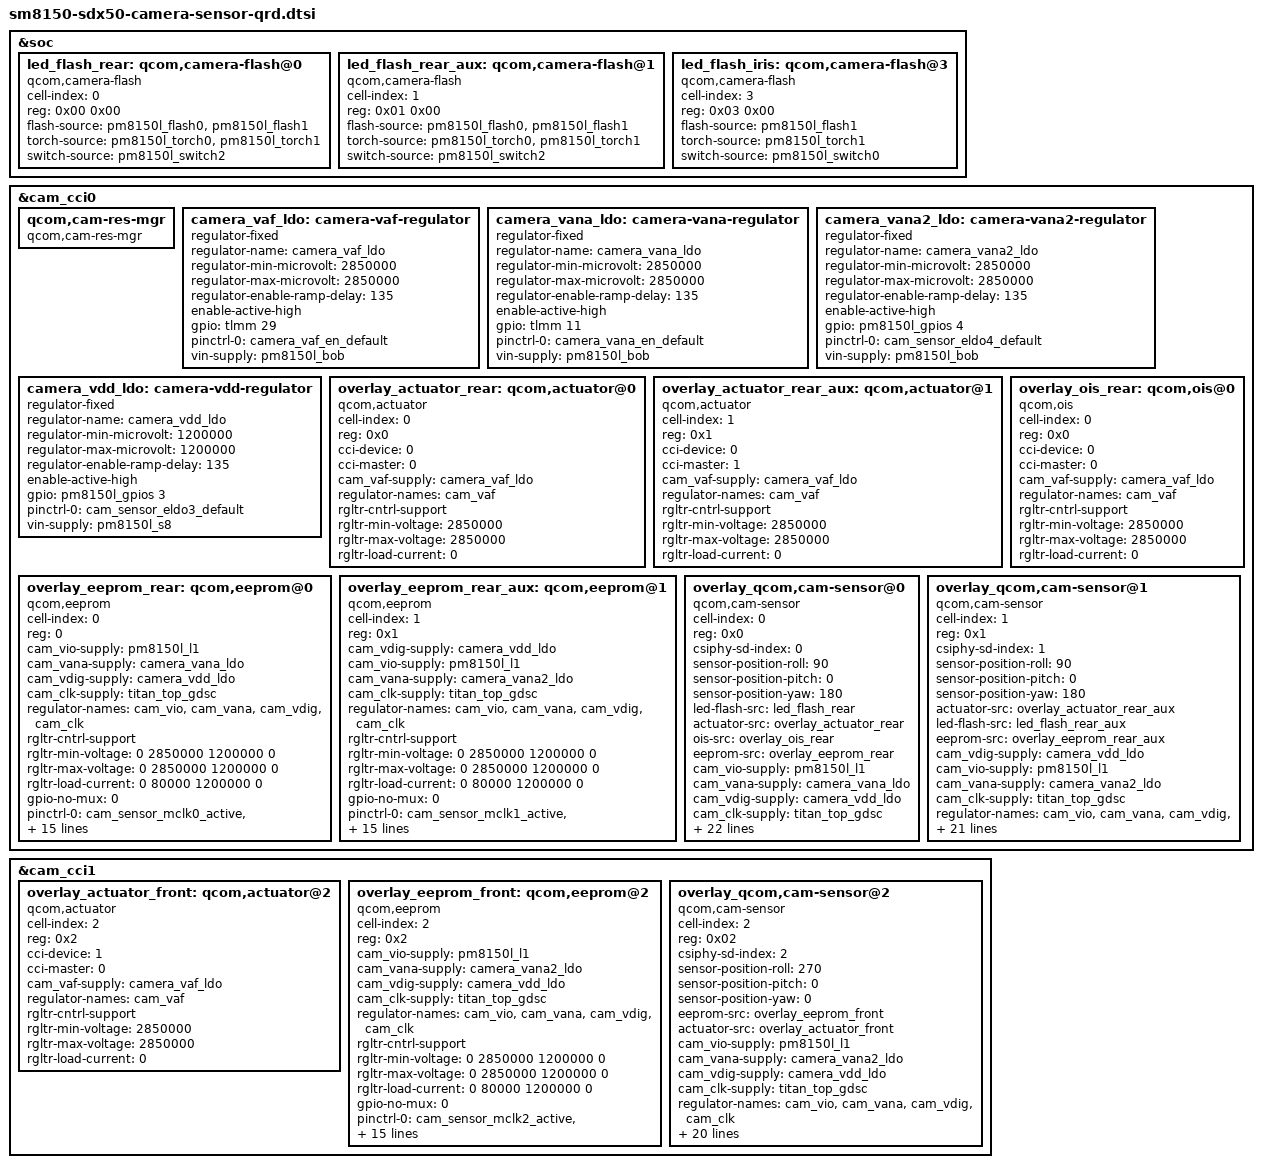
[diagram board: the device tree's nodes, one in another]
/*
 * Copyright (c) 2018-2019 The Linux Foundation. All rights reserved.
 *
 * This program is free software; you can redistribute it and/or modify
 * it under the terms of the GNU General Public License version 2 and
 * only version 2 as published by the Free Software Foundation.
 *
 * This program is distributed in the hope that it will be useful,
 * but WITHOUT ANY WARRANTY; without even the implied warranty of
 * MERCHANTABILITY or FITNESS FOR A PARTICULAR PURPOSE.  See the
 * GNU General Public License for more details.
 */

#include <dt-bindings/clock/qcom,camcc-sm8150.h>

&soc {
	#address-cells = <1>;
	#size-cells = <1>;

	led_flash_rear: qcom,camera-flash@0 {
		cell-index = <0>;
		reg = <0x00 0x00>;
		compatible = "qcom,camera-flash";
		flash-source = <&pm8150l_flash0 &pm8150l_flash1>;
		torch-source = <&pm8150l_torch0 &pm8150l_torch1>;
		switch-source = <&pm8150l_switch2>;
		status = "ok";
	};

	led_flash_rear_aux: qcom,camera-flash@1 {
		cell-index = <1>;
		reg = <0x01 0x00>;
		compatible = "qcom,camera-flash";
		flash-source = <&pm8150l_flash0 &pm8150l_flash1>;
		torch-source = <&pm8150l_torch0 &pm8150l_torch1>;
		switch-source = <&pm8150l_switch2>;
		status = "ok";
	};

	led_flash_iris: qcom,camera-flash@3 {
		cell-index = <3>;
		reg = <0x03 0x00>;
		compatible = "qcom,camera-flash";
		flash-source = <&pm8150l_flash1>;
		torch-source = <&pm8150l_torch1>;
		switch-source = <&pm8150l_switch0>;
		status = "ok";
	};
};

&cam_cci0 {
	#address-cells = <1>;
	#size-cells = <0>;

	qcom,cam-res-mgr {
		compatible = "qcom,cam-res-mgr";
		status = "ok";
	};
	camera_vaf_ldo: camera-vaf-regulator {
		compatible = "regulator-fixed";
		regulator-name = "camera_vaf_ldo";
		regulator-min-microvolt = <2850000>;
		regulator-max-microvolt = <2850000>;
		regulator-enable-ramp-delay = <135>; //Check
		enable-active-high;
		gpio = <&tlmm 29 0>;
		pinctrl-names = "default";
		pinctrl-0 = <&camera_vaf_en_default>;
		vin-supply = <&pm8150l_bob>;
	};

	camera_vana_ldo: camera-vana-regulator {
		compatible = "regulator-fixed";
		regulator-name = "camera_vana_ldo";
		regulator-min-microvolt = <2850000>;
		regulator-max-microvolt = <2850000>;
		regulator-enable-ramp-delay = <135>; // Check
		enable-active-high;
		gpio = <&tlmm 11 0>;
		pinctrl-names = "default";
		pinctrl-0 = <&camera_vana_en_default>;
		vin-supply = <&pm8150l_bob>;
	};

	camera_vana2_ldo: camera-vana2-regulator {
		compatible = "regulator-fixed";
		regulator-name = "camera_vana2_ldo";
		regulator-min-microvolt = <2850000>;
		regulator-max-microvolt = <2850000>;
		regulator-enable-ramp-delay = <135>; // Check
		enable-active-high;
		gpio = <&pm8150l_gpios 4 0>;
		pinctrl-names = "default";
		pinctrl-0 = <&cam_sensor_eldo4_default>;
		vin-supply = <&pm8150l_bob>;
	};

	camera_vdd_ldo: camera-vdd-regulator {
		compatible = "regulator-fixed";
		regulator-name = "camera_vdd_ldo";
		regulator-min-microvolt = <1200000>;
		regulator-max-microvolt = <1200000>;
		regulator-enable-ramp-delay = <135>; // Check
		enable-active-high;
		gpio = <&pm8150l_gpios 3 0>;
		pinctrl-names = "default";
		pinctrl-0 = <&cam_sensor_eldo3_default>;
		vin-supply = <&pm8150l_s8>;
	};

	overlay_actuator_rear: qcom,actuator@0 {
		cell-index = <0>;
		reg = <0x0>;
		compatible = "qcom,actuator";
		cci-device = <0>;
		cci-master = <0>;
		cam_vaf-supply = <&camera_vaf_ldo>;
		regulator-names = "cam_vaf";
		rgltr-cntrl-support;
		rgltr-min-voltage = <2850000>;
		rgltr-max-voltage = <2850000>;
		rgltr-load-current = <0>;
	};

	overlay_actuator_rear_aux: qcom,actuator@1 {
		cell-index = <1>;
		reg = <0x1>;
		compatible = "qcom,actuator";
		cci-device = <0>;
		cci-master = <1>;
		cam_vaf-supply = <&camera_vaf_ldo>;
		regulator-names = "cam_vaf";
		rgltr-cntrl-support;
		rgltr-min-voltage = <2850000>;
		rgltr-max-voltage = <2850000>;
		rgltr-load-current = <0>;
	};

	overlay_ois_rear: qcom,ois@0 {
		cell-index = <0>;
		reg = <0x0>;
		compatible = "qcom,ois";
		cci-device = <0>;
		cci-master = <0>;
		cam_vaf-supply = <&camera_vaf_ldo>;
		regulator-names = "cam_vaf";
		rgltr-cntrl-support;
		rgltr-min-voltage = <2850000>;
		rgltr-max-voltage = <2850000>;
		rgltr-load-current = <0>;
		status = "ok";
	};

	overlay_eeprom_rear: qcom,eeprom@0 {
		cell-index = <0>;
		reg = <0>;
		compatible = "qcom,eeprom";
		cam_vio-supply = <&pm8150l_l1>;
		cam_vana-supply = <&camera_vana_ldo>;
		cam_vdig-supply = <&camera_vdd_ldo>;
		cam_clk-supply = <&titan_top_gdsc>;
		regulator-names = "cam_vio", "cam_vana", "cam_vdig",
			"cam_clk";
		rgltr-cntrl-support;
		rgltr-min-voltage = <0 2850000 1200000 0>;
		rgltr-max-voltage = <0 2850000 1200000 0>;
		rgltr-load-current = <0 80000 1200000 0>;
		gpio-no-mux = <0>;
		pinctrl-names = "cam_default", "cam_suspend";
		pinctrl-0 = <&cam_sensor_mclk0_active
				&cam_sensor_active_rear>;
		pinctrl-1 = <&cam_sensor_mclk0_suspend
				&cam_sensor_suspend_rear>;
		gpios = <&tlmm 13 0>,
			<&tlmm 28 0>;
		gpio-reset = <1>;
		gpio-req-tbl-num = <0 1>;
		gpio-req-tbl-flags = <1 0>;
		gpio-req-tbl-label = "CAMIF_MCLK0",
					"CAM_RESET0";
		sensor-position = <0>;
		sensor-mode = <0>;
		cci-device = <0>;
		cci-master = <0>;
		status = "ok";
		clocks = <&clock_camcc CAM_CC_MCLK0_CLK>;
		clock-names = "cam_clk";
		clock-cntl-level = "turbo";
		clock-rates = <24000000>;
	};

	overlay_eeprom_rear_aux: qcom,eeprom@1 {
		cell-index = <1>;
		reg = <0x1>;
		compatible = "qcom,eeprom";
		cam_vdig-supply = <&camera_vdd_ldo>;
		cam_vio-supply = <&pm8150l_l1>;
		cam_vana-supply = <&camera_vana2_ldo>;
		cam_clk-supply = <&titan_top_gdsc>;
		regulator-names = "cam_vio", "cam_vana", "cam_vdig",
			"cam_clk";
		rgltr-cntrl-support;
		rgltr-min-voltage = <0 2850000 1200000 0>;
		rgltr-max-voltage = <0 2850000 1200000 0>;
		rgltr-load-current = <0 80000 1200000 0>;
		gpio-no-mux = <0>;
		pinctrl-names = "cam_default", "cam_suspend";
		pinctrl-0 = <&cam_sensor_mclk1_active
				 &cam_sensor_active_rear_aux>;
		pinctrl-1 = <&cam_sensor_mclk1_suspend
				 &cam_sensor_suspend_rear_aux>;
		gpios = <&tlmm 14 0>,
			<&tlmm 30 0>;
		gpio-reset = <1>;
		gpio-req-tbl-num = <0 1>;
		gpio-req-tbl-flags = <1 0>;
		gpio-req-tbl-label = "CAMIF_MCLK1",
					"CAM_RESET1";
		sensor-position = <0>;
		sensor-mode = <0>;
		cci-device = <0>;
		cci-master = <1>;
		status = "ok";
		clocks = <&clock_camcc CAM_CC_MCLK2_CLK>;
		clock-names = "cam_clk";
		clock-cntl-level = "turbo";
		clock-rates = <24000000>;
	};

	overlay_qcom,cam-sensor@0 {
		cell-index = <0>;
		compatible = "qcom,cam-sensor";
		reg = <0x0>;
		csiphy-sd-index = <0>;
		sensor-position-roll = <90>;
		sensor-position-pitch = <0>;
		sensor-position-yaw = <180>;
		led-flash-src = <&led_flash_rear>;
		actuator-src = <&overlay_actuator_rear>;
		ois-src = <&overlay_ois_rear>;
		eeprom-src = <&overlay_eeprom_rear>;
		cam_vio-supply = <&pm8150l_l1>;
		cam_vana-supply = <&camera_vana_ldo>;
		cam_vdig-supply = <&camera_vdd_ldo>;
		cam_clk-supply = <&titan_top_gdsc>;
		regulator-names = "cam_vio", "cam_vana", "cam_vdig",
			"cam_clk";
		rgltr-cntrl-support;
		rgltr-min-voltage = <0 2850000 1200000 0>;
		rgltr-max-voltage = <0 2850000 1200000 0>;
		rgltr-load-current = <0 80000 1200000 0>;
		gpio-no-mux = <0>;
		pinctrl-names = "cam_default", "cam_suspend";
		pinctrl-0 = <&cam_sensor_mclk0_active
				&cam_sensor_active_rear>;
		pinctrl-1 = <&cam_sensor_mclk0_suspend
				&cam_sensor_suspend_rear>;
		gpios = <&tlmm 13 0>,
			<&tlmm 28 0>;
		gpio-reset = <1>;
		gpio-req-tbl-num = <0 1>;
		gpio-req-tbl-flags = <1 0>;
		gpio-req-tbl-label = "CAMIF_MCLK0",
					"CAM_RESET0";
		sensor-mode = <0>;
		cci-device = <0>;
		cci-master = <0>;
		status = "ok";
		clocks = <&clock_camcc CAM_CC_MCLK0_CLK>;
		clock-names = "cam_clk";
		clock-cntl-level = "turbo";
		clock-rates = <24000000>;
	};

	overlay_qcom,cam-sensor@1 {
		cell-index = <1>;
		compatible = "qcom,cam-sensor";
		reg = <0x1>;
		csiphy-sd-index = <1>;
		sensor-position-roll = <90>;
		sensor-position-pitch = <0>;
		sensor-position-yaw = <180>;
		actuator-src = <&overlay_actuator_rear_aux>;
		led-flash-src = <&led_flash_rear_aux>;
		eeprom-src = <&overlay_eeprom_rear_aux>;
		cam_vdig-supply = <&camera_vdd_ldo>;
		cam_vio-supply = <&pm8150l_l1>;
		cam_vana-supply = <&camera_vana2_ldo>;
		cam_clk-supply = <&titan_top_gdsc>;
		regulator-names = "cam_vio", "cam_vana", "cam_vdig",
			"cam_clk";
		rgltr-cntrl-support;
		rgltr-min-voltage = <0 2850000 1200000 0>;
		rgltr-max-voltage = <0 2850000 1200000 0>;
		rgltr-load-current = <0 80000 1200000 0>;
		gpio-no-mux = <0>;
		pinctrl-names = "cam_default", "cam_suspend";
		pinctrl-0 = <&cam_sensor_mclk1_active
				&cam_sensor_active_rear_aux>;
		pinctrl-1 = <&cam_sensor_mclk1_suspend
				&cam_sensor_suspend_rear_aux>;
		gpios = <&tlmm 14 0>,
			<&tlmm 30 0>;
		gpio-reset = <1>;
		gpio-req-tbl-num = <0 1>;
		gpio-req-tbl-flags = <1 0>;
		gpio-req-tbl-label = "CAMIF_MCLK1",
					"CAM_RESET1";
		sensor-mode = <0>;
		cci-device = <0>;
		cci-master = <1>;
		status = "ok";
		clocks = <&clock_camcc CAM_CC_MCLK1_CLK>;
		clock-names = "cam_clk";
		clock-cntl-level = "turbo";
		clock-rates = <24000000>;
	};
};

&cam_cci1 {
	#address-cells = <1>;
	#size-cells = <0>;
	overlay_actuator_front: qcom,actuator@2 {
		cell-index = <2>;
		reg = <0x2>;
		compatible = "qcom,actuator";
		cci-device = <1>;
		cci-master = <0>;
		cam_vaf-supply = <&camera_vaf_ldo>;
		regulator-names = "cam_vaf";
		rgltr-cntrl-support;
		rgltr-min-voltage = <2850000>;
		rgltr-max-voltage = <2850000>;
		rgltr-load-current = <0>;
	};
	overlay_eeprom_front: qcom,eeprom@2 {
		cell-index = <2>;
		reg = <0x2>;
		compatible = "qcom,eeprom";
		cam_vio-supply = <&pm8150l_l1>;
		cam_vana-supply = <&camera_vana2_ldo>;
		cam_vdig-supply = <&camera_vdd_ldo>;
		cam_clk-supply = <&titan_top_gdsc>;
		regulator-names = "cam_vio", "cam_vana", "cam_vdig",
			"cam_clk";
		rgltr-cntrl-support;
		rgltr-min-voltage = <0 2850000 1200000 0>;
		rgltr-max-voltage = <0 2850000 1200000 0>;
		rgltr-load-current = <0 80000 1200000 0>;
		gpio-no-mux = <0>;
		pinctrl-names = "cam_default", "cam_suspend";
		pinctrl-0 = <&cam_sensor_mclk2_active
				 &cam_sensor_active_front>;
		pinctrl-1 = <&cam_sensor_mclk2_suspend
				 &cam_sensor_suspend_front>;
		gpios = <&tlmm 15 0>,
			<&tlmm 12 0>;
		gpio-reset = <1>;
		gpio-req-tbl-num = <0 1>;
		gpio-req-tbl-flags = <1 0>;
		gpio-req-tbl-label = "CAMIF_MCLK2",
					"CAM_RESET2";
		sensor-position = <1>;
		sensor-mode = <0>;
		cci-device = <1>;
		cci-master = <0>;
		status = "ok";
		clocks = <&clock_camcc CAM_CC_MCLK2_CLK>;
		clock-names = "cam_clk";
		clock-cntl-level = "turbo";
		clock-rates = <24000000>;
	};
	overlay_qcom,cam-sensor@2 {
		cell-index = <2>;
		compatible = "qcom,cam-sensor";
		reg = <0x02>;
		csiphy-sd-index = <2>;
		sensor-position-roll = <270>;
		sensor-position-pitch = <0>;
		sensor-position-yaw = <0>;
		eeprom-src = <&overlay_eeprom_front>;
		actuator-src = <&overlay_actuator_front>;
		cam_vio-supply = <&pm8150l_l1>;
		cam_vana-supply = <&camera_vana2_ldo>;
		cam_vdig-supply = <&camera_vdd_ldo>;
		cam_clk-supply = <&titan_top_gdsc>;
		regulator-names = "cam_vio", "cam_vana", "cam_vdig",
			"cam_clk";
		rgltr-cntrl-support;
		rgltr-min-voltage = <0 2850000 1200000 0>;
		rgltr-max-voltage = <0 2850000 1200000 0>;
		rgltr-load-current = <0 80000 1200000 0>;
		gpio-no-mux = <0>;
		pinctrl-names = "cam_default", "cam_suspend";
		pinctrl-0 = <&cam_sensor_mclk2_active
				 &cam_sensor_active_front>;
		pinctrl-1 = <&cam_sensor_mclk2_suspend
				 &cam_sensor_suspend_front>;
		gpios = <&tlmm 15 0>,
			<&tlmm 12 0>;
		gpio-reset = <1>;
		gpio-req-tbl-num = <0 1>;
		gpio-req-tbl-flags = <1 0>;
		gpio-req-tbl-label = "CAMIF_MCLK2",
					"CAM_RESET2";
		sensor-mode = <0>;
		cci-device = <1>;
		cci-master = <0>;
		status = "ok";
		clocks = <&clock_camcc CAM_CC_MCLK2_CLK>;
		clock-names = "cam_clk";
		clock-cntl-level = "turbo";
		clock-rates = <24000000>;
	};
};
